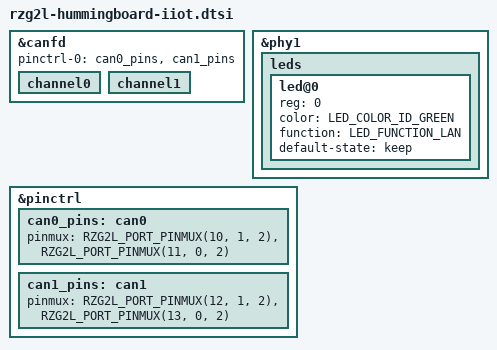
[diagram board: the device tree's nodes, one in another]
// SPDX-License-Identifier: (GPL-2.0-only OR BSD-2-Clause)
/*
 * Copyright 2025 Josua Mayer <josua@solid-run.com>
 */

#include "rzg2l-hummingboard-iiot-common.dtsi"

&canfd {
	pinctrl-names = "default";
	pinctrl-0 = <&can0_pins>, <&can1_pins>;
	status = "okay";

	channel0 {
		status = "okay";
	};

	channel1 {
		status = "okay";
	};
};

&phy1 {
	leds {
		#address-cells = <1>;
		#size-cells = <0>;

		/* LED_0 pin */
		led@0 {
			reg = <0>;
			color = <LED_COLOR_ID_GREEN>;
			function = LED_FUNCTION_LAN;
			default-state = "keep";
		};
	};
};

&pinctrl {
	/* CANA */
	can0_pins: can0 {
		pinmux = <RZG2L_PORT_PINMUX(10, 1, 2)>, /* CAN0_TX */
			 <RZG2L_PORT_PINMUX(11, 0, 2)>; /* CAN0_RX */
	};

	/* CANB */
	can1_pins: can1 {
		pinmux = <RZG2L_PORT_PINMUX(12, 1, 2)>, /* CAN1_TX */
			 <RZG2L_PORT_PINMUX(13, 0, 2)>; /* CAN1_RX */
	};
};
